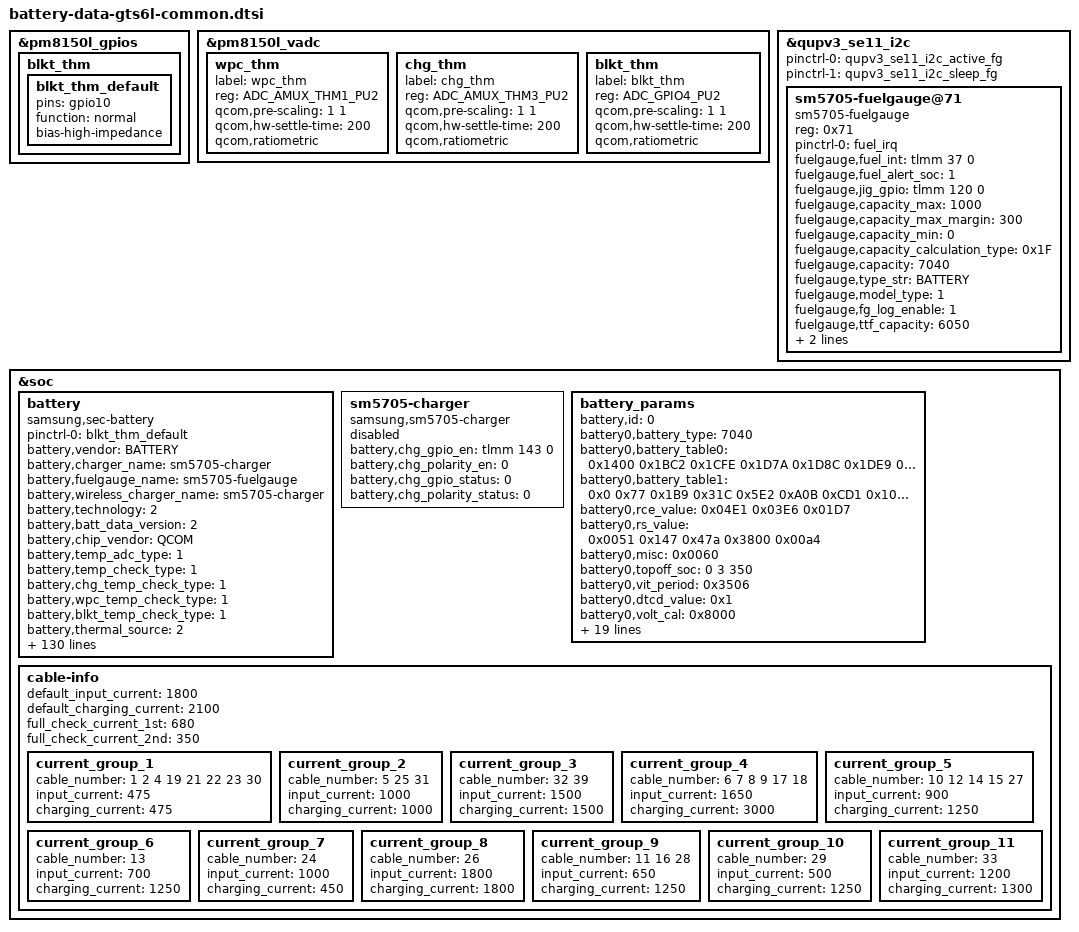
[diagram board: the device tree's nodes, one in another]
/* Copyright (c) 2014, The Linux Foundation. All rights reserved.
 *
 * This program is free software; you can redistribute it and/or modify
 * it under the terms of the GNU General Public License version 2 and
 * only version 2 as published by the Free Software Foundation.
 *
 * This program is distributed in the hope that it will be useful,
 * but WITHOUT ANY WARRANTY; without even the implied warranty of
 * MERCHANTABILITY or FITNESS FOR A PARTICULAR PURPOSE.  See the
 * GNU General Public License for more details.
 */

&pm8150l_gpios {
	blkt_thm { /* GPIO_10 */
		blkt_thm_default: blkt_thm_default {
			pins = "gpio10";
			function = "normal";
			bias-high-impedance;
		};
	};
};

&pm8150l_vadc {
	wpc_thm { /* AMUX_1 */
		label = "wpc_thm";
		reg = <ADC_AMUX_THM1_PU2>;
		qcom,pre-scaling = <1 1>;
		qcom,hw-settle-time = <200>;
		qcom,ratiometric;
	};
	chg_thm { /* AMUX_3 */
		label = "chg_thm";
		reg = <ADC_AMUX_THM3_PU2>;
		qcom,pre-scaling = <1 1>;
		qcom,hw-settle-time = <200>;
		qcom,ratiometric;
	};
	blkt_thm { /* GPIO_10 */
		label = "blkt_thm";
		reg = <ADC_GPIO4_PU2>;
		qcom,pre-scaling = <1 1>;
		qcom,hw-settle-time = <200>;
		qcom,ratiometric;
	};
};

&qupv3_se11_i2c {
	status = "ok";

	pinctrl-0 = <&qupv3_se11_i2c_active_fg>;
	pinctrl-1 = <&qupv3_se11_i2c_sleep_fg>;
	
	sm5705-fuelgauge@71 {
		compatible = "sm5705-fuelgauge";
		reg = <0x71>;
		pinctrl-names = "default";
		pinctrl-0 = <&fuel_irq>;
		fuelgauge,fuel_int = <&tlmm 37 0>;
		fuelgauge,fuel_alert_soc = <1>;
		fuelgauge,jig_gpio = <&tlmm 120 0>; /* IFC_SENSE_INT_AP */
		fuelgauge,capacity_max = <1000>;
		fuelgauge,capacity_max_margin = <300>;
		fuelgauge,capacity_min = <0>;
		fuelgauge,capacity_calculation_type = <0x1F>;
		fuelgauge,capacity = <7040>;
		fuelgauge,type_str = "BATTERY";
		fuelgauge,model_type = <1>;
		fuelgauge,fg_log_enable = <1>;

		fuelgauge,ttf_capacity = <6050>;
		fuelgauge,cv_data = <
			3011	860	1740
			2984	870	1672
			2815	880	1582
			2704	890	1514
			2545	900	1427
			2377	910	1332
			2232	920	1224
			2051	930	1116
			1905	940	1002
			1720	950	842
			1541	960	711
			1397	970	563
			1262	980	383
			1102	990	173
			680	1000	0
		>;
	};
};

&soc {
	battery {
		status = "okay";
		compatible = "samsung,sec-battery";
		pinctrl-names = "default";
		pinctrl-0 = <&blkt_thm_default>;
		battery,vendor = "BATTERY";
		battery,charger_name = "sm5705-charger";
		battery,fuelgauge_name = "sm5705-fuelgauge";
		battery,wireless_charger_name = "sm5705-charger";
		battery,technology = <2>; /* POWER_SUPPLY_TECHNOLOGY_LION */

		battery,batt_data_version = <2>;

		battery,chip_vendor = "QCOM";
		battery,temp_adc_type = <1>; /* SEC_BATTERY_ADC_TYPE_AP */

		battery,temp_check_type = <1>; /* SEC_BATTERY_TEMP_CHECK_ADC */
		battery,chg_temp_check_type = <1>;
		battery,wpc_temp_check_type = <1>;  // 0 /* SEC_BATTERY_TEMP_CHECK_NONE */
		battery,blkt_temp_check_type = <1>;

		battery,thermal_source = <2>; /* SEC_BATTERY_THERMAL_SOURCE_ADC */
		battery,chg_thermal_source = <2>; /* SEC_BATTERY_THERMAL_SOURCE_ADC */
		battery,wpc_thermal_source = <2>; /* SEC_BATTERY_THERMAL_SOURCE_ADC */
		battery,blkt_thermal_source = <2>; /* SEC_BATTERY_THERMAL_SOURCE_ADC */

		battery,polling_time = <10 30 30 30 3600>;

		battery,temp_table_adc = <135474 157813 185337 214309 252558
						293518 334443 390311 456581 531754
						619520 712889 813227 911605 1019131
						1138465 1246597 1349725 1444578 1528676
						1600266 1664820 1715866>;
		battery,temp_table_data = <900 850 800 750 700
						650 600 550 500 450
						400 350 300 250 200
						150 100 50 0 (-50)
						(-100) (-150) (-200)>;

		battery,chg_temp_table_adc = <129598 151520 177948 207172 246359
						289626 327645 381170 449048 520033
						606134 702400 799668 904310 1002154
						1122765 1235978 1341205 1436872 1518569
						1586936 1654166 1709414>;
		battery,chg_temp_table_data = <900 850 800 750 700
						650 600 550 500 450
						400 350 300 250 200
						150 100 50 0 (-50)
						(-100) (-150) (-200)>;

		battery,wpc_temp_table_adc = <135474 157813 185337 214309 252558
						293518 334443 390311 456581 531754
						619520 712889 813227 911605 1019131
						1138465 1246597 1349725 1444578 1528676
						1600266 1664820 1715866>;
		battery,wpc_temp_table_data = <900 850 800 750 700
						650 600 550 500 450
						400 350 300 250 200
						150 100 50 0 (-50)
						(-100) (-150) (-200)>;

		battery,blkt_temp_table_adc = <128164 150425 177623 207244 245912
						285748 327472 381552 448175 517913
						604757 703351 800684 909241 1009414
						1125014 1238090 1340058 1434753 1517798
						1588285 1655608 1709025>;
		battery,blkt_temp_table_data = <900 850 800 750 700
						650 600 550 500 450
						400 350 300 250 200
						150 100 50 0 (-50)
						(-100) (-150) (-200)>;

		battery,adc_check_count = <5>;

		battery,cable_check_type = <4>; /* SEC_BATTERY_CABLE_CHECK_PSY */
		battery,cable_source_type = <1>; /* SEC_BATTERY_CABLE_SOURCE_EXTERNAL */
		battery,polling_type = <1>; /* SEC_BATTERY_MONITOR_ALARM */
		battery,monitor_initial_count = <0>;

		battery,battery_check_type = <0>; /* SEC_BATTERY_CHECK_NONE */
		battery,check_count = <0>;
		battery,check_adc_max = <1440>;
		battery,check_adc_min = <0>;

		battery,ovp_uvlo_check_type = <3>; /* SEC_BATTERY_OVP_UVLO_CHGPOLLING */

		battery,temp_check_count = <1>;
		battery,temp_highlimit_threshold_event = <800>;
		battery,temp_highlimit_recovery_event = <780>;
		battery,temp_high_threshold_event = <500>;
		battery,temp_high_recovery_event = <450>;
		battery,temp_low_threshold_event = <0>;
		battery,temp_low_recovery_event = <50>;
		battery,temp_highlimit_threshold_normal = <800>;
		battery,temp_highlimit_recovery_normal = <780>;
		battery,temp_high_threshold_normal = <500>;
		battery,temp_high_recovery_normal = <450>;
		battery,temp_low_threshold_normal = <0>;
		battery,temp_low_recovery_normal = <50>;
		battery,temp_highlimit_threshold_lpm = <800>;
		battery,temp_highlimit_recovery_lpm = <780>;
		battery,temp_high_threshold_lpm = <500>;
		battery,temp_high_recovery_lpm = <450>;
		battery,temp_low_threshold_lpm = <0>;
		battery,temp_low_recovery_lpm = <50>;
		battery,full_check_type = <2>; /* SEC_BATTERY_FULLCHARGED_FG_CURRENT */
		battery,full_check_type_2nd = <2>; /* SEC_BATTERY_FULLCHARGED_FG_CURRENT */
		battery,full_check_count = <1>;
		battery,chg_gpio_full_check = <0>;
		battery,chg_polarity_full_check = <1>;

		battery,chg_high_temp = <800>;
		battery,chg_high_temp_recovery = <770>;
		battery,chg_input_limit_current = <1000>;
		battery,chg_charging_limit_current = <1500>;

		battery,store_mode_afc_input_current = <700>;

		battery,sleep_mode_limit_current = <800>;

		battery,mix_high_temp = <410>;
		battery,mix_high_chg_temp = <595>;
		battery,mix_high_temp_recovery = <380>;

		/* SEC_BATTERY_FULL_CONDITION_NOTIMEFULL | SEC_BATTERY_FULL_CONDITION_VCELL */
		battery,full_condition_type = <9>;
		battery,full_condition_soc = <93>;
		battery,full_condition_vcell = <4250>;

		battery,recharge_check_count = <1>;
		battery,recharge_condition_type = <4>; /* SEC_BATTERY_RECHARGE_CONDITION_VCELL */
		battery,recharge_condition_soc = <98>;
		battery,recharge_condition_vcell = <4280>;

		battery,charging_total_time = <14400>;
		battery,hv_charging_total_time = <10800>;
		battery,normal_charging_total_time = <18000>;
		battery,usb_charging_total_time = <36000>;
		battery,recharging_total_time = <5400>;
		battery,charging_reset_time = <0>;

		battery,chg_float_voltage = <4350>;
		battery,chg_ocp_current = <5600>;

		battery,pre_afc_work_delay = <2000>;
		battery,pre_wc_afc_work_delay = <4000>;
		battery,pre_afc_input_current = <500>;
		battery,pre_wc_afc_input_current = <500>;
		battery,prepare_ta_delay = <0>; /* msec */

		battery,swelling_high_temp_block = <410>;
		battery,swelling_high_temp_recov = <390>;
		battery,swelling_low_temp_block_1st = <150>;
		battery,swelling_low_temp_recov_1st = <200>;
		battery,swelling_low_temp_block_2nd = <50>;
		battery,swelling_low_temp_recov_2nd = <100>;
		battery,swelling_low_temp_current = <1200>;
		battery,swelling_low_temp_current_2nd = <1200>;
		battery,swelling_low_temp_topoff = <350>;
		battery,swelling_high_temp_current = <1800>;
		battery,swelling_high_temp_topoff = <350>;

		battery,swelling_drop_float_voltage = <4150>;
		battery,swelling_high_rechg_voltage = <4000>;
		battery,swelling_low_rechg_thr = <150>;

		battery,swelling_drop_float_voltage_lowtemp;
		battery,swelling_low_rechg_voltage = <4000>;

		battery,siop_input_limit_current = <1200>;
		battery,siop_charging_limit_current = <1000>;
		battery,siop_hv_input_limit_current = <700>;
		battery,siop_hv_input_limit_current_2nd = <550>;
		battery,siop_hv_charging_limit_current = <1000>;

		battery,ttf_hv_charge_current = <2650>;
		battery,ttf_pogo_charge_current = <1170>;

		battery,rp_current_rp1 = <475>;
		battery,rp_current_rp2 = <1400>;
		battery,rp_current_rp3 = <3000>;
		battery,rp_current_rdu_rp3 = <2100>;
		battery,rp_current_abnormal_rp3 = <1800>;

		battery,pd_charging_charge_power = <15000>;
		battery,max_charging_current = <3000>;

		/* cycle, chg_float_voltage, recharge_condition_vcell, full_condition_vcell, full_condition_soc */
		battery,age_data = <0 4350 4280 4250 93
				300 4330 4260 4230 92
				400 4310 4240 4210 91
				700 4290 4220 4190 90
				1000 4240 4170 4140 89>;

		battery,max_input_voltage = <9000>; /* mV */
		battery,max_input_current = <3000>;  /* mA */

		battery,enable_sysovlo_irq;

		battery,standard_curr = <3000>;
		battery,expired_time = <15000>;
		battery,recharging_expired_time = <5400>;

		battery,battery_full_capacity = <7040>;
		battery,cisd_max_voltage_thr = <4400>; /* batttery ovp dettection voltage */
		battery,cisd_alg_index = <8>;
		battery,ignore_cisd_index = <0 0>;
		battery,ignore_cisd_index_d = <0 120>; /* Do not use AFC_FAIL_PER_DAY to DROP_VALUE_PER_DAY */ 

		io-channels = <&pm8150l_vadc ADC_AMUX_THM1_PU2>, <&pm8150l_vadc ADC_AMUX_THM3_PU2>, <&pm8150l_vadc ADC_AMUX_THM1_PU2>, <&pm8150l_vadc ADC_GPIO4_PU2>;
		io-channel-names = "adc-temp", "adc-chg-temp", "adc-wpc-temp", "adc-blkt-temp";
	};

	sm5705-charger {
		status = "disable";
		compatible = "samsung,sm5705-charger";
		battery,chg_gpio_en = <&tlmm 143 0>;
		battery,chg_polarity_en = <0>;
		battery,chg_gpio_status = <0>;
		battery,chg_polarity_status = <0>;
	};

	battery_params {
		battery,id = <0>; /* -1 means auto, detected by F/G */
		battery0,battery_type = <7040>; /* 4200 4350 4400 */
		battery0,battery_table0 = <0x1400 0x1BC2 0x1CFE 0x1D7A 0x1D8C 0x1DE9 0x1E0C 0x1E41 0x1E88 0x1EF0 0x1F6A 0x1FF8 0x207F 0x20E0 0x2235 0x2400>;
		battery0,battery_table1 = <0x0 0x77 0x1B9 0x31C 0x5E2 0xA0B 0xCD1 0x10FA 0x17E9 0x1D75 0x203B 0x25C7 0x288D 0x2B53 0x32D0 0x32EA>;
		battery0,rce_value = <0x04E1 0x03E6 0x01D7>;
		battery0,rs_value = <0x0051 0x147 0x47a 0x3800 0x00a4>; /*rs p_mix_factor n_mix_factor max min*/
		battery0,misc = <0x0060>;
		battery0,topoff_soc = <0 3 350>; /*disable soc current*/
		battery0,vit_period = <0x3506>;
		battery0,dtcd_value = <0x1>;
		battery0,volt_cal = <0x8000>;
		battery0,curr_offset = <1 0x0000>; /*en_auto offset*/
		battery0,p_curr_cal = <0x0099>;
		battery0,n_curr_cal = <0x00B6>;
		battery0,mix_value = <0x0503 0x0004>; /*mix_rate init_blank*/
		battery0,temp_std = <25>;
		battery0,temp_cal = <1 6 1 11 (-1) 1 6 1 9 1>; /* en_h, p_de, p_fa, n_de, n_fa, en_l, p_de, p_fa, n_de, n_fa, */
		battery0,ext_temp_cal = <1 3 0 3 1 1 2 3 2 3>; /* en_h, p_de, p_fa, n_de, n_fa, en_l, p_de, p_fa, n_de, n_fa, */
		battery0,temp_volcal = <1 15 1>; /* en, temp, cal */
		battery0,temp_offset = <1 11 1 1 8 (-1)>; /* en_high level offset en_low level offset */
		battery0,cycle_cfg = <7 1 3>; /*high_limit low_limit cntl*/
		battery0,curr_lcal = <0 0x8888 0x8888 0x8888>;
		battery0,tem_poff = <3380 50 3320 50>;
		battery0,v_offset_cancel = <1 0 100 10>; /* en_p, en_n, level, mohm */
		battery0,v_alarm = <3000>;
		battery0,v_max_table = <0x2235 0x21EE 0x21C6 0x219E 0x213B>;
		battery0,q_max_table = <0x32D0 0x32C7 0x31DB 0x30EF 0x2EA2>;

		battery0,data_ver = <0x06>;
	};

/* sec_battery_cable
 *   0	UNKNOWN,
 *   1	NONE,
 *   2	PREPARE_TA,
 *   3	TA,
 *   4	USB,
 *   5	USB_CDP,
 *   6	9V_TA,
 *   7	9V_ERR,
 *   8	9V_UNKNOWN,
 *   9	12V_TA,
 *  10	WIRELESS,
 *  11	HV_WIRELESS,
 *  12	PMA_WIRELESS,
 *  13	WIRELESS_PACK,
 *  14	CABLE_WIRELESS_HV_PACK,
 *  15	WIRELESS_STAND,
 *  16	WIRELESS_HV_STAND,
 *  17	QC20,
 *  18	QC30,
 *  19	PDIC,
 *  20	UARTOFF,
 *  21	OTG,
 *  22	LAN_HUB,
 *  23	POWER_SHARING,
 *  24	HMT_CONNECTED,
 *  25	HMT_CHARGE,
 *  26	HV_TA_CHG_LIMIT,
 *  27	WIRELESS_VEHICLE,
 *  28	WIRELESS_HV_VEHICLE,
 *  29	PREPARE_WIRELESS_HV,
 *  30  TIMEOUT,
 *  31  SMART_OTG,
 *  32  SMART_NOTG,
 *  33  WIRELESS_TX,
 *  34	HV_WIRELESS_20,
 *  35	HV_WIRELESS_20_LIMIT,
 *  36	WIRELESS_FAKE,
 *  37  PREPARE_WIRELESS_20,
 *  38	CABLE_PDIC_APDO,
 *  39	CABLE_POGO,
 *  40	CABLE_MAX,
 */
	cable-info {
		default_input_current = <1800>;
		default_charging_current = <2100>;
		full_check_current_1st = <680>;
		full_check_current_2nd = <350>;

		current_group_1 {
			cable_number = <1 2 4 19 21 22 23 30>;
			input_current = <475>;
			charging_current = <475>;
		};
		current_group_2 {
			cable_number = <5 25 31>;
			input_current = <1000>;
			charging_current = <1000>;
		};
		current_group_3 {
			cable_number = <32 39>;
			input_current = <1500>;
			charging_current = <1500>;
		};
		current_group_4 {
			cable_number = <6 7 8 9 17 18>;
			input_current = <1650>;
			charging_current = <3000>;
		};
		current_group_5 {
			cable_number = <10 12 14 15 27>;
			input_current = <900>;
			charging_current = <1250>;
		};
		current_group_6 {
			cable_number = <13>;
			input_current = <700>;
			charging_current = <1250>;
		};
		current_group_7 {
			cable_number = <24>;
			input_current = <1000>;
			charging_current = <450>;
		};
		current_group_8 {
			cable_number = <26>;
			input_current = <1800>;
			charging_current = <1800>;
		};
		current_group_9 {
			cable_number = <11 16 28>;
			input_current = <650>;
			charging_current = <1250>;
		};
		current_group_10 {
			cable_number = <29>;
			input_current = <500>;
			charging_current = <1250>;
		};
		current_group_11 {
			cable_number = <33>;
			input_current = <1200>;
			charging_current = <1300>;
		};
	};
};
